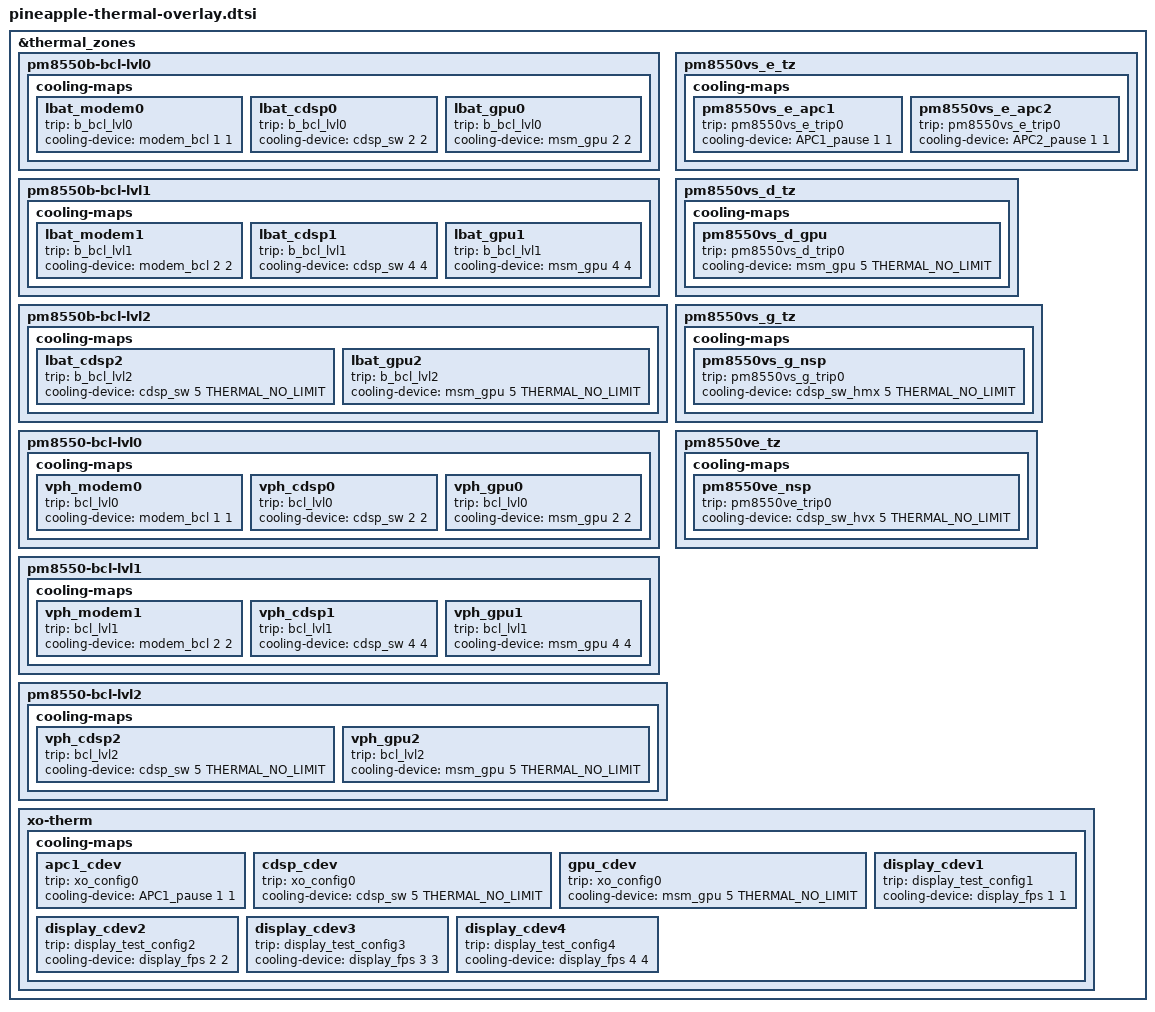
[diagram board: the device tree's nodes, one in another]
#include <dt-bindings/thermal/thermal_qti.h>

&thermal_zones {
	pm8550b-bcl-lvl0 {
		cooling-maps {
			lbat_modem0 {
				trip = <&b_bcl_lvl0>;
				cooling-device = <&modem_bcl 1 1>;
			};

			lbat_cdsp0 {
				trip = <&b_bcl_lvl0>;
				cooling-device = <&cdsp_sw 2 2>;
			};

			lbat_gpu0 {
				trip = <&b_bcl_lvl0>;
				cooling-device = <&msm_gpu 2 2>;
			};
		};
	};

	pm8550b-bcl-lvl1 {
		cooling-maps {
			lbat_modem1 {
				trip = <&b_bcl_lvl1>;
				cooling-device = <&modem_bcl 2 2>;
			};

			lbat_cdsp1 {
				trip = <&b_bcl_lvl1>;
				cooling-device = <&cdsp_sw 4 4>;
			};

			lbat_gpu1 {
				trip = <&b_bcl_lvl1>;
				cooling-device = <&msm_gpu 4 4>;
			};
		};
	};

	pm8550b-bcl-lvl2 {
		cooling-maps {
			lbat_cdsp2 {
				trip = <&b_bcl_lvl2>;
				cooling-device = <&cdsp_sw 5 THERMAL_NO_LIMIT>;
			};

			lbat_gpu2 {
				trip = <&b_bcl_lvl2>;
				cooling-device = <&msm_gpu 5 THERMAL_NO_LIMIT>;
			};
		};
	};

	pm8550-bcl-lvl0 {
		cooling-maps {
			vph_modem0 {
				trip = <&bcl_lvl0>;
				cooling-device = <&modem_bcl 1 1>;
			};

			vph_cdsp0 {
				trip = <&bcl_lvl0>;
				cooling-device = <&cdsp_sw 2 2>;
			};

			vph_gpu0 {
				trip = <&bcl_lvl0>;
				cooling-device = <&msm_gpu 2 2>;
			};
		};
	};

	pm8550-bcl-lvl1 {
		cooling-maps {
			vph_modem1 {
				trip = <&bcl_lvl1>;
				cooling-device = <&modem_bcl 2 2>;
			};

			vph_cdsp1 {
				trip = <&bcl_lvl1>;
				cooling-device = <&cdsp_sw 4 4>;
			};

			vph_gpu1 {
				trip = <&bcl_lvl1>;
				cooling-device = <&msm_gpu 4 4>;
			};
		};
	};

	pm8550-bcl-lvl2 {
		cooling-maps {
			vph_cdsp2 {
				trip = <&bcl_lvl2>;
				cooling-device = <&cdsp_sw 5 THERMAL_NO_LIMIT>;
			};

			vph_gpu2 {
				trip = <&bcl_lvl2>;
				cooling-device = <&msm_gpu 5 THERMAL_NO_LIMIT>;
			};
		};
	};

	pm8550vs_e_tz {
		cooling-maps {
			pm8550vs_e_apc1 {
				trip = <&pm8550vs_e_trip0>;
				cooling-device = <&APC1_pause 1 1>;
			};

			pm8550vs_e_apc2 {
				trip = <&pm8550vs_e_trip0>;
				cooling-device = <&APC2_pause 1 1>;
			};
		};
	};

	pm8550vs_d_tz {
		cooling-maps {
			pm8550vs_d_gpu {
				trip = <&pm8550vs_d_trip0>;
				cooling-device = <&msm_gpu 5 THERMAL_NO_LIMIT>;
			};
		};
	};

	pm8550vs_g_tz {
		cooling-maps {
			pm8550vs_g_nsp {
				trip = <&pm8550vs_g_trip0>;
				cooling-device = <&cdsp_sw_hmx 5 THERMAL_NO_LIMIT>;
			};
		};
	};

	pm8550ve_tz {
		cooling-maps {
			pm8550ve_nsp {
				trip = <&pm8550ve_trip0>;
				cooling-device = <&cdsp_sw_hvx 5 THERMAL_NO_LIMIT>;
			};
		};
	};

	xo-therm {
		cooling-maps {
			apc1_cdev {
				trip = <&xo_config0>;
				cooling-device = <&APC1_pause 1 1>;
			};

			cdsp_cdev {
				trip = <&xo_config0>;
				cooling-device = <&cdsp_sw 5 THERMAL_NO_LIMIT>;
			};

			gpu_cdev {
				trip = <&xo_config0>;
				cooling-device = <&msm_gpu 5 THERMAL_NO_LIMIT>;
			};

			display_cdev1 {
				trip = <&display_test_config1>;
				cooling-device = <&display_fps 1 1>;
			};

			display_cdev2 {
				trip = <&display_test_config2>;
				cooling-device = <&display_fps 2 2>;
			};

			display_cdev3 {
				trip = <&display_test_config3>;
				cooling-device = <&display_fps 3 3>;
			};

			display_cdev4 {
				trip = <&display_test_config4>;
				cooling-device = <&display_fps 4 4>;
			};
		};
	};
};
